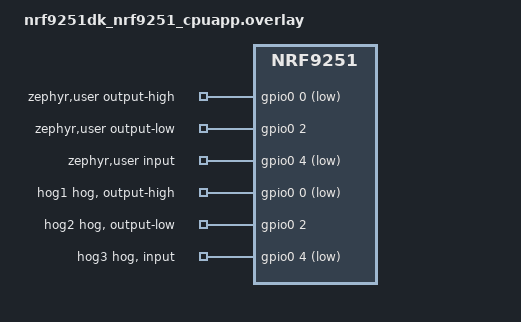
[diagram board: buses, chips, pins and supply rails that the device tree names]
#include <zephyr/dt-bindings/gpio/gpio.h>

/ {
	zephyr,user {
		output-high-gpios = <&gpio0 0 GPIO_ACTIVE_LOW>;
		output-low-gpios = <&gpio0 2 GPIO_ACTIVE_HIGH>;
		input-gpios = <&gpio0 4 GPIO_ACTIVE_LOW>;
	};
};

&gpio0 {
	status = "okay";

	hog1 {
		gpio-hog;
		gpios = <0 GPIO_ACTIVE_LOW>;
		output-high;
	};

	hog2 {
		gpio-hog;
		gpios = <2 GPIO_ACTIVE_HIGH>;
		output-low;
	};

	hog3 {
		gpio-hog;
		gpios = <4 GPIO_ACTIVE_LOW>;
		input;
	};
};

&gpiote130 {
	status = "okay";
};
